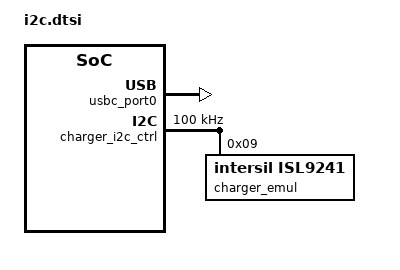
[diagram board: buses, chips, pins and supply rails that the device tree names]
/* Copyright 2024 The ChromiumOS Authors
 * Use of this source code is governed by a BSD-style license that can be
 * found in the LICENSE file.
 */

/ {
	usbc {
		#address-cells = <1>;
		#size-cells = <0>;

		usbc_port0: port0@0 {
			compatible = "named-usbc-port";
			reg = <0>;
			chg = <&charger_emul>;
	        };
	};

	named-i2c-ports {
		compatible = "named-i2c-ports";

		i2c_charger: charger {
			i2c-port = <&charger_i2c_ctrl>;
			enum-names = "I2C_PORT_CHARGER",
				"I2C_PORT_BATTERY",
				"I2C_PORT_EEPROM",
				"I2C_PORT_KB_DISCRETE",
				"I2C_PORT_PORT80";
		};
	};

	charger_i2c_ctrl: charger_i2c_ctrl@700 {
		status = "okay";
		compatible = "zephyr,i2c-emul-controller";
		clock-frequency = <I2C_BITRATE_STANDARD>;
		#address-cells = <1>;
		#size-cells = <0>;
		reg = <0x700 6>;

	        charger_emul: isl9241@9 {
			compatible = "intersil,isl9241";
			status = "okay";
			reg = <0x9>;
	        };

		/* kb_discrete: ite-it8801@39 {
			compatible = "ite,it8801","cros,i2c-mock";
			reg = <0x39>;
		};*/
	};
};
